VERSION ""

NS_ :

BS_:

BU_: BMS TESTER

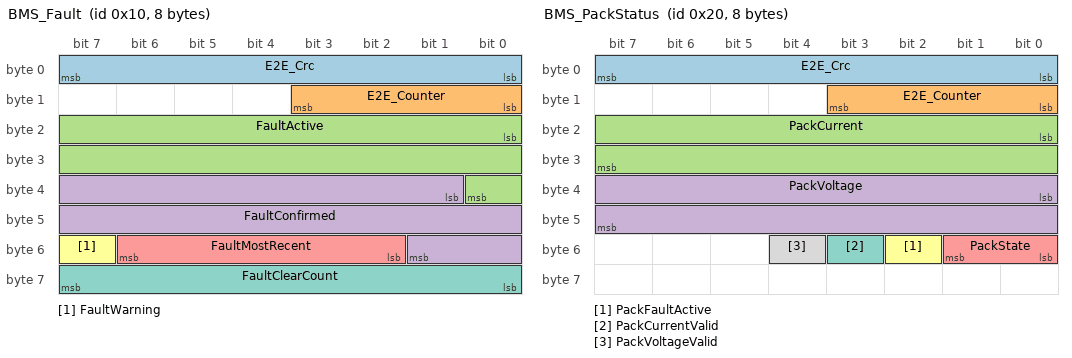
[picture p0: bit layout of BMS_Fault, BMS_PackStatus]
BO_ 16 BMS_Fault: 8 BMS
 SG_ E2E_Crc : 0|8@1+ (1,0) [0|255] "" TESTER
 SG_ E2E_Counter : 8|4@1+ (1,0) [0|14] "" TESTER
 SG_ FaultActive : 16|17@1+ (1,0) [0|131071] "" TESTER
 SG_ FaultConfirmed : 33|17@1+ (1,0) [0|131071] "" TESTER
 SG_ FaultMostRecent : 50|5@1+ (1,0) [0|16] "" TESTER
 SG_ FaultWarning : 55|1@1+ (1,0) [0|1] "" TESTER
 SG_ FaultClearCount : 56|8@1+ (1,0) [0|255] "" TESTER

BO_ 32 BMS_PackStatus: 8 BMS
 SG_ E2E_Crc : 0|8@1+ (1,0) [0|255] "" TESTER
 SG_ E2E_Counter : 8|4@1+ (1,0) [0|14] "" TESTER
 SG_ PackCurrent : 16|16@1- (0.01,0) [-327.68|327.67] "A" TESTER
 SG_ PackVoltage : 32|16@1+ (0.001,0) [0|65.535] "V" TESTER
 SG_ PackState : 48|2@1+ (1,0) [0|2] "" TESTER
 SG_ PackFaultActive : 50|1@1+ (1,0) [0|1] "" TESTER
 SG_ PackCurrentValid : 51|1@1+ (1,0) [0|1] "" TESTER
 SG_ PackVoltageValid : 52|1@1+ (1,0) [0|1] "" TESTER

BO_ 48 BMS_Heartbeat: 8 BMS
 SG_ PeriodCounter : 0|32@1+ (1,0) [0|4294967295] "" TESTER
 SG_ TickCount : 32|32@1+ (1,0) [0|4294967295] "tick" TESTER

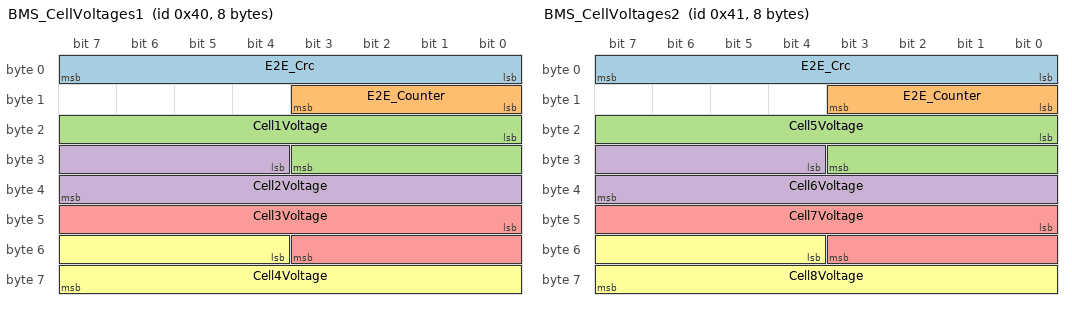
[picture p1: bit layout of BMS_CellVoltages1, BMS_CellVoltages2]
BO_ 64 BMS_CellVoltages1: 8 BMS
 SG_ E2E_Crc : 0|8@1+ (1,0) [0|255] "" TESTER
 SG_ E2E_Counter : 8|4@1+ (1,0) [0|14] "" TESTER
 SG_ Cell1Voltage : 16|12@1+ (0.001,1) [1|5.094] "V" TESTER
 SG_ Cell2Voltage : 28|12@1+ (0.001,1) [1|5.094] "V" TESTER
 SG_ Cell3Voltage : 40|12@1+ (0.001,1) [1|5.094] "V" TESTER
 SG_ Cell4Voltage : 52|12@1+ (0.001,1) [1|5.094] "V" TESTER

BO_ 65 BMS_CellVoltages2: 8 BMS
 SG_ E2E_Crc : 0|8@1+ (1,0) [0|255] "" TESTER
 SG_ E2E_Counter : 8|4@1+ (1,0) [0|14] "" TESTER
 SG_ Cell5Voltage : 16|12@1+ (0.001,1) [1|5.094] "V" TESTER
 SG_ Cell6Voltage : 28|12@1+ (0.001,1) [1|5.094] "V" TESTER
 SG_ Cell7Voltage : 40|12@1+ (0.001,1) [1|5.094] "V" TESTER
 SG_ Cell8Voltage : 52|12@1+ (0.001,1) [1|5.094] "V" TESTER

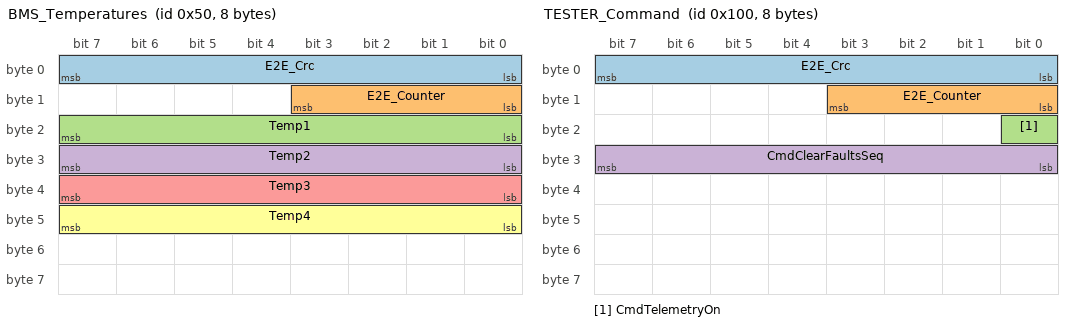
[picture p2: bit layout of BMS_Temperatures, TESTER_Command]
BO_ 80 BMS_Temperatures: 8 BMS
 SG_ E2E_Crc : 0|8@1+ (1,0) [0|255] "" TESTER
 SG_ E2E_Counter : 8|4@1+ (1,0) [0|14] "" TESTER
 SG_ Temp1 : 16|8@1+ (1,-40) [-40|214] "degC" TESTER
 SG_ Temp2 : 24|8@1+ (1,-40) [-40|214] "degC" TESTER
 SG_ Temp3 : 32|8@1+ (1,-40) [-40|214] "degC" TESTER
 SG_ Temp4 : 40|8@1+ (1,-40) [-40|214] "degC" TESTER

BO_ 256 TESTER_Command: 8 TESTER
 SG_ E2E_Crc : 0|8@1+ (1,0) [0|255] "" BMS
 SG_ E2E_Counter : 8|4@1+ (1,0) [0|14] "" BMS
 SG_ CmdTelemetryOn : 16|1@1+ (1,0) [0|1] "" BMS
 SG_ CmdClearFaultsSeq : 24|8@1+ (1,0) [0|255] "" BMS

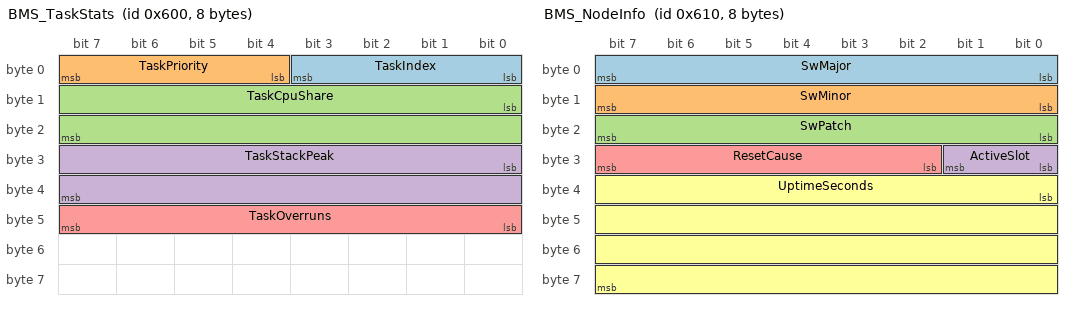
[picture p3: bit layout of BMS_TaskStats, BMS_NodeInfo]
BO_ 1536 BMS_TaskStats: 8 BMS
 SG_ TaskIndex : 0|4@1+ (1,0) [0|15] "" TESTER
 SG_ TaskPriority : 4|4@1+ (1,0) [0|15] "" TESTER
 SG_ TaskCpuShare : 8|16@1+ (0.01,0) [0|100] "%" TESTER
 SG_ TaskStackPeak : 24|16@1+ (1,0) [0|65535] "byte" TESTER
 SG_ TaskOverruns : 40|8@1+ (1,0) [0|255] "" TESTER

BO_ 1552 BMS_NodeInfo: 8 BMS
 SG_ SwMajor : 0|8@1+ (1,0) [0|255] "" TESTER
 SG_ SwMinor : 8|8@1+ (1,0) [0|255] "" TESTER
 SG_ SwPatch : 16|8@1+ (1,0) [0|255] "" TESTER
 SG_ ActiveSlot : 24|2@1+ (1,0) [0|1] "" TESTER
 SG_ ResetCause : 26|6@1+ (1,0) [0|62] "" TESTER
 SG_ UptimeSeconds : 32|32@1+ (1,0) [0|4294967295] "s" TESTER

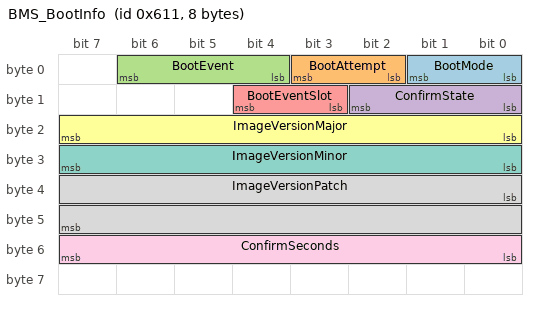
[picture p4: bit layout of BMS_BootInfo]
BO_ 1553 BMS_BootInfo: 8 BMS
 SG_ BootMode : 0|2@1+ (1,0) [0|2] "" TESTER
 SG_ BootAttempt : 2|2@1+ (1,0) [0|3] "" TESTER
 SG_ BootEvent : 4|3@1+ (1,0) [0|7] "" TESTER
 SG_ ConfirmState : 8|3@1+ (1,0) [0|4] "" TESTER
 SG_ BootEventSlot : 11|2@1+ (1,0) [0|1] "" TESTER
 SG_ ImageVersionMajor : 16|8@1+ (1,0) [0|255] "" TESTER
 SG_ ImageVersionMinor : 24|8@1+ (1,0) [0|255] "" TESTER
 SG_ ImageVersionPatch : 32|16@1+ (1,0) [0|65535] "" TESTER
 SG_ ConfirmSeconds : 48|8@1+ (1,0) [0|255] "s" TESTER

BO_ 1776 TESTER_Ping: 8 TESTER

BO_ 1777 BMS_Pong: 8 BMS

BO_ 2016 UDS_Request: 8 TESTER

BO_ 2024 UDS_Response: 8 BMS

CM_ "freertos-can-node: every frame the node sends or accepts, base format (11-bit identifiers), little-endian signals. A lower identifier wins arbitration, so identifiers are handed out by urgency. Messages with an FcnE2eDataId of 0 or more are protected by AUTOSAR E2E Profile 11, variant 11A (docs/can-protocol.md).";
CM_ BU_ BMS "The node: a FreeRTOS telemetry node for one battery module.";
CM_ BU_ TESTER "Whatever talks to the node: the test bench, a diagnostic tool.";
CM_ BO_ 16 "The node's diagnostic trouble codes, every 100 ms, sent by the task that owns them after the last change it made in the period, so that every change goes out in the frame of the period that made it: a fault that became active and passed again within the period is active in that frame. Protected end to end. Fault n (the value table of FaultMostRecent, app/fault.h) is bit n of FaultActive and FaultConfirmed.";
CM_ SG_ 16 E2E_Crc "E2E Profile 11 CRC over the Data ID and bytes 1 to 7.";
CM_ SG_ 16 E2E_Counter "E2E Profile 11 counter: 0 to 14, then 0 again; 15 is never sent.";
CM_ SG_ 16 FaultActive "Bit n: the DTC of fault n has testFailed (ISO 14229-1 status bit 0) at the end of the period, or its testFailed rose during the period (after the clear, if the period had one): the fault is present, or was present since the last frame. PackFaultActive is 1 while any bit is.";
CM_ SG_ 16 FaultConfirmed "Bit n: the DTC of fault n has confirmedDTC (status bit 3): the fault occurred since the node started or since the last clear (CmdClearFaultsSeq).";
CM_ SG_ 16 FaultMostRecent "The fault whose DTC went to testFailed most recently since the start or the last clear; NONE if none did.";
CM_ SG_ 16 FaultWarning "1 while a DTC requests the warning indicator (status bit 7): a limit of the pack was exceeded, or its measurement failed, since the start or the last clear.";
CM_ SG_ 16 FaultClearCount "Clears of the DTCs carried out since the node started, modulo 256.";
CM_ BO_ 32 "Pack summary, every 10 ms. Protected end to end.";
CM_ SG_ 32 E2E_Crc "E2E Profile 11 CRC over the Data ID and bytes 1 to 7.";
CM_ SG_ 32 E2E_Counter "E2E Profile 11 counter: 0 to 14, then 0 again; 15 is never sent.";
CM_ SG_ 32 PackCurrent "Filtered pack current, positive while the pack is discharging; meaningful only while PackCurrentValid is 1.";
CM_ SG_ 32 PackVoltage "Sum of the filtered cell voltages; meaningful only while PackVoltageValid is 1.";
CM_ SG_ 32 PackState "STARTUP until every channel has delivered a reading, FAULT while a channel is invalid or a fault is active (PackFaultActive), NORMAL otherwise.";
CM_ SG_ 32 PackFaultActive "1 while a fault is active: a bit of FaultActive is set in the last BMS_Fault, so a DTC had testFailed at the end of the fault owner's last 100 ms period or its testFailed rose during it.";
CM_ SG_ 32 PackCurrentValid "1 if PackCurrent holds a valid, filtered measurement.";
CM_ SG_ 32 PackVoltageValid "1 if every cell voltage is valid, so that PackVoltage is their sum.";
CM_ BO_ 48 "Heartbeat, every 10 ms: the status frame of phase 1, unchanged. The node keeps the latest value in a slot of its transmit queue, so a value not yet sent is replaced by the next one, and a missing counter value means it was replaced. Not protected end to end.";
CM_ SG_ 48 PeriodCounter "Number of 10 ms periods the node has run since it started; the first frame carries 1. A period it skipped after an overrun is not counted, so the counter never jumps; TickCount shows the time.";
CM_ SG_ 48 TickCount "The node's FreeRTOS tick count when it published the frame (1 tick = 1 ms).";
CM_ BO_ 64 "Filtered voltages of cells 1 to 4, every 20 ms. Protected end to end.";
CM_ SG_ 64 E2E_Crc "E2E Profile 11 CRC over the Data ID and bytes 1 to 7.";
CM_ SG_ 64 E2E_Counter "E2E Profile 11 counter: 0 to 14, then 0 again; 15 is never sent.";
CM_ SG_ 64 Cell1Voltage "Raw 4095 (SNA): no valid measurement. Voltages below 1.000 V are sent as 1.000 V, above 5.094 V as 5.094 V.";
CM_ SG_ 64 Cell2Voltage "As Cell1Voltage.";
CM_ SG_ 64 Cell3Voltage "As Cell1Voltage.";
CM_ SG_ 64 Cell4Voltage "As Cell1Voltage.";
CM_ BO_ 65 "Filtered voltages of cells 5 to 8, every 20 ms. Protected end to end.";
CM_ SG_ 65 E2E_Crc "E2E Profile 11 CRC over the Data ID and bytes 1 to 7.";
CM_ SG_ 65 E2E_Counter "E2E Profile 11 counter: 0 to 14, then 0 again; 15 is never sent.";
CM_ SG_ 65 Cell5Voltage "As Cell1Voltage of BMS_CellVoltages1.";
CM_ SG_ 65 Cell6Voltage "As Cell1Voltage of BMS_CellVoltages1.";
CM_ SG_ 65 Cell7Voltage "As Cell1Voltage of BMS_CellVoltages1.";
CM_ SG_ 65 Cell8Voltage "As Cell1Voltage of BMS_CellVoltages1.";
CM_ BO_ 80 "Filtered temperatures, every 100 ms. Protected end to end.";
CM_ SG_ 80 E2E_Crc "E2E Profile 11 CRC over the Data ID and bytes 1 to 7.";
CM_ SG_ 80 E2E_Counter "E2E Profile 11 counter: 0 to 14, then 0 again; 15 is never sent.";
CM_ SG_ 80 Temp1 "Raw 255 (SNA): no valid measurement. Temperatures below -40 degC are sent as -40 degC, above 214 degC as 214 degC.";
CM_ SG_ 80 Temp2 "As Temp1.";
CM_ SG_ 80 Temp3 "As Temp1.";
CM_ SG_ 80 Temp4 "As Temp1.";
CM_ BO_ 256 "Commands to the node, sent cyclically every 100 ms so that their loss is detectable. Protected end to end.";
CM_ SG_ 256 E2E_Crc "E2E Profile 11 CRC over the Data ID and bytes 1 to 7.";
CM_ SG_ 256 E2E_Counter "E2E Profile 11 counter: 0 to 14, then 0 again; 15 is never sent.";
CM_ SG_ 256 CmdTelemetryOn "0 silences the protected cyclic telemetry (BMS_PackStatus, BMS_CellVoltages1, BMS_CellVoltages2, BMS_Temperatures); the heartbeat, the task statistics and the node information go on. The node behaves as if 1 until a valid command has arrived.";
CM_ SG_ 256 CmdClearFaultsSeq "The node clears its DTCs whenever this value changes from one command it carries out to the next while the command stream stays valid; the first command carried out after the stream started or was lost only sets the reference.";
CM_ BO_ 1536 "Run-time statistics of one task per frame; the node cycles through its tasks, one frame every 200 ms. Not protected end to end.";
CM_ SG_ 1536 TaskIndex "Which task this frame describes: 0 to the number of tasks minus 1.";
CM_ SG_ 1536 TaskPriority "The task's FreeRTOS priority.";
CM_ SG_ 1536 TaskCpuShare "Share of the CPU time the task used since the node started.";
CM_ SG_ 1536 TaskStackPeak "Deepest stack use seen, saturated at 65535.";
CM_ SG_ 1536 TaskOverruns "Periods in which the task missed its deadline, saturated at 255.";
CM_ BO_ 1552 "Identity and status of the node, once per second. Not protected end to end.";
CM_ SG_ 1552 SwMajor "Software version, major number.";
CM_ SG_ 1552 SwMinor "Software version, minor number.";
CM_ SG_ 1552 SwPatch "Software version, patch number.";
CM_ SG_ 1552 ActiveSlot "The firmware slot the node runs from, as the bootloader's hand-off names it; SNA for a node started without the bootloader. BMS_BootInfo says whether the image runs as a trial.";
CM_ SG_ 1552 ResetCause "Why the node was last reset: the values of plat_reset_reason_t; POWER_ON for a start without a reset before it; SNA while the node does not know.";
CM_ SG_ 1552 UptimeSeconds "Seconds since the node started.";
CM_ BO_ 1553 "The image the node runs and its update state, once per second: the companion of BMS_NodeInfo, whose 64 bits are all in use. Taken from the bootloader's hand-off at start, except ConfirmState and ConfirmSeconds, which follow the confirm of a trial. Not protected end to end.";
CM_ SG_ 1553 BootMode "How the bootloader started the image: as the CONFIRMED image, as a TRIAL that confirms itself once it has run in good health, or NONE: the node was started without the bootloader (no hand-off), and every other signal of this message but ConfirmState is 0.";
CM_ SG_ 1553 BootAttempt "For a TRIAL, the attempt this start is: 1 to 3 (a trial is rolled back when its third start does not confirm it); 0 otherwise.";
CM_ SG_ 1553 BootEvent "The state change the bootloader made before this start: ADOPT (the factory image became the confirmed one), ROLLBACK (a trial used its 3 attempts), REJECT (a trial did not validate), FALLBACK (the confirmed image did not validate; the one before it runs again), or NONE. ROLLBACK, REJECT and FALLBACK set the DTC UPDATE_ROLLBACK (BMS_Fault).";
CM_ SG_ 1553 ConfirmState "NOT_NEEDED: the image is not a trial. WAITING: a trial counting its time in good health (ConfirmSeconds). CONFIRMING: the confirm is being written. CONFIRMED: this trial confirmed itself and is the active image. FAILED: the confirm could not be written; the trial will be rolled back after its attempts.";
CM_ SG_ 1553 BootEventSlot "The slot BootEvent acted on: the adopted slot (ADOPT), the rejected trial's (ROLLBACK, REJECT), or the slot fallen back to, whose image is the confirmed one again (FALLBACK); SNA for none.";
CM_ SG_ 1553 ImageVersionMajor "The version of the running image as its header gives it (major.minor.patch); 0 without the bootloader.";
CM_ SG_ 1553 ImageVersionMinor "As ImageVersionMajor.";
CM_ SG_ 1553 ImageVersionPatch "As ImageVersionMajor.";
CM_ SG_ 1553 ConfirmSeconds "For a trial: the seconds of good health counted towards its confirm (the watchdog manager OK, the controller error active and not bus off since the period before, and a frame of the node acknowledged since then, in every 100 ms period without a break), saturated at 255; the confirm is made at 5.";
CM_ BO_ 1776 "Echo request: any payload of 0 to 8 bytes. No signals; used for link tests and latency measurements.";
CM_ BO_ 1777 "Echo reply: the payload of the request, 0 to 8 bytes.";
CM_ BO_ 2016 "Diagnostic requests, ISO 15765-2 frames (phase 5). No signals.";
CM_ BO_ 2024 "Diagnostic responses, ISO 15765-2 frames (phase 5). No signals.";

BA_DEF_ "BusType" STRING ;
BA_DEF_ "Baudrate" INT 0 1000000;
BA_DEF_ BO_ "GenMsgCycleTime" INT 0 65535;
BA_DEF_ BO_ "FcnE2eDataId" INT -1 65535;
BA_DEF_DEF_ "BusType" "CAN";
BA_DEF_DEF_ "Baudrate" 500000;
BA_DEF_DEF_ "GenMsgCycleTime" 0;
BA_DEF_DEF_ "FcnE2eDataId" -1;
BA_ "GenMsgCycleTime" BO_ 16 100;
BA_ "GenMsgCycleTime" BO_ 32 10;
BA_ "GenMsgCycleTime" BO_ 48 10;
BA_ "GenMsgCycleTime" BO_ 64 20;
BA_ "GenMsgCycleTime" BO_ 65 20;
BA_ "GenMsgCycleTime" BO_ 80 100;
BA_ "GenMsgCycleTime" BO_ 256 100;
BA_ "GenMsgCycleTime" BO_ 1536 200;
BA_ "GenMsgCycleTime" BO_ 1552 1000;
BA_ "GenMsgCycleTime" BO_ 1553 1000;
BA_ "FcnE2eDataId" BO_ 16 272;
BA_ "FcnE2eDataId" BO_ 32 288;
BA_ "FcnE2eDataId" BO_ 64 320;
BA_ "FcnE2eDataId" BO_ 65 321;
BA_ "FcnE2eDataId" BO_ 80 336;
BA_ "FcnE2eDataId" BO_ 256 512;

VAL_ 16 FaultMostRecent 0 "CELL_OVERVOLTAGE" 1 "CELL_UNDERVOLTAGE" 2 "OVERTEMPERATURE" 3 "UNDERTEMPERATURE" 4 "OVERCURRENT_DISCHARGE" 5 "OVERCURRENT_CHARGE" 6 "SENSOR_CHANNEL_INVALID" 7 "FRONT_END_NO_ANSWER" 8 "SAMPLE_TIMEOUT" 9 "CAN_BUS_OFF" 10 "CAN_ERROR_PASSIVE" 11 "SUPERVISION_EXPIRED" 12 "RESET_WATCHDOG" 13 "RESET_ASSERT" 14 "RESET_STACK_OVERFLOW" 15 "RESET_MALLOC_FAILED" 16 "UPDATE_ROLLBACK" 31 "NONE" ;
VAL_ 32 PackState 0 "STARTUP" 1 "NORMAL" 2 "FAULT" ;
VAL_ 64 Cell1Voltage 4095 "SNA" ;
VAL_ 64 Cell2Voltage 4095 "SNA" ;
VAL_ 64 Cell3Voltage 4095 "SNA" ;
VAL_ 64 Cell4Voltage 4095 "SNA" ;
VAL_ 65 Cell5Voltage 4095 "SNA" ;
VAL_ 65 Cell6Voltage 4095 "SNA" ;
VAL_ 65 Cell7Voltage 4095 "SNA" ;
VAL_ 65 Cell8Voltage 4095 "SNA" ;
VAL_ 80 Temp1 255 "SNA" ;
VAL_ 80 Temp2 255 "SNA" ;
VAL_ 80 Temp3 255 "SNA" ;
VAL_ 80 Temp4 255 "SNA" ;
VAL_ 1552 ActiveSlot 0 "A" 1 "B" 3 "SNA" ;
VAL_ 1553 BootMode 0 "NONE" 1 "CONFIRMED" 2 "TRIAL" ;
VAL_ 1553 BootEvent 0 "NONE" 1 "ADOPT" 5 "ROLLBACK" 6 "REJECT" 7 "FALLBACK" ;
VAL_ 1553 ConfirmState 0 "NOT_NEEDED" 1 "WAITING" 2 "CONFIRMING" 3 "CONFIRMED" 4 "FAILED" ;
VAL_ 1553 BootEventSlot 0 "A" 1 "B" 3 "SNA" ;
VAL_ 1552 ResetCause 0 "POWER_ON" 10 "REQUESTED" 11 "WATCHDOG" 12 "POWER_LOSS" 13 "IMAGE_FAULT" 20 "ASSERT" 21 "STACK_OVERFLOW" 22 "MALLOC_FAILED" 63 "SNA" ;
